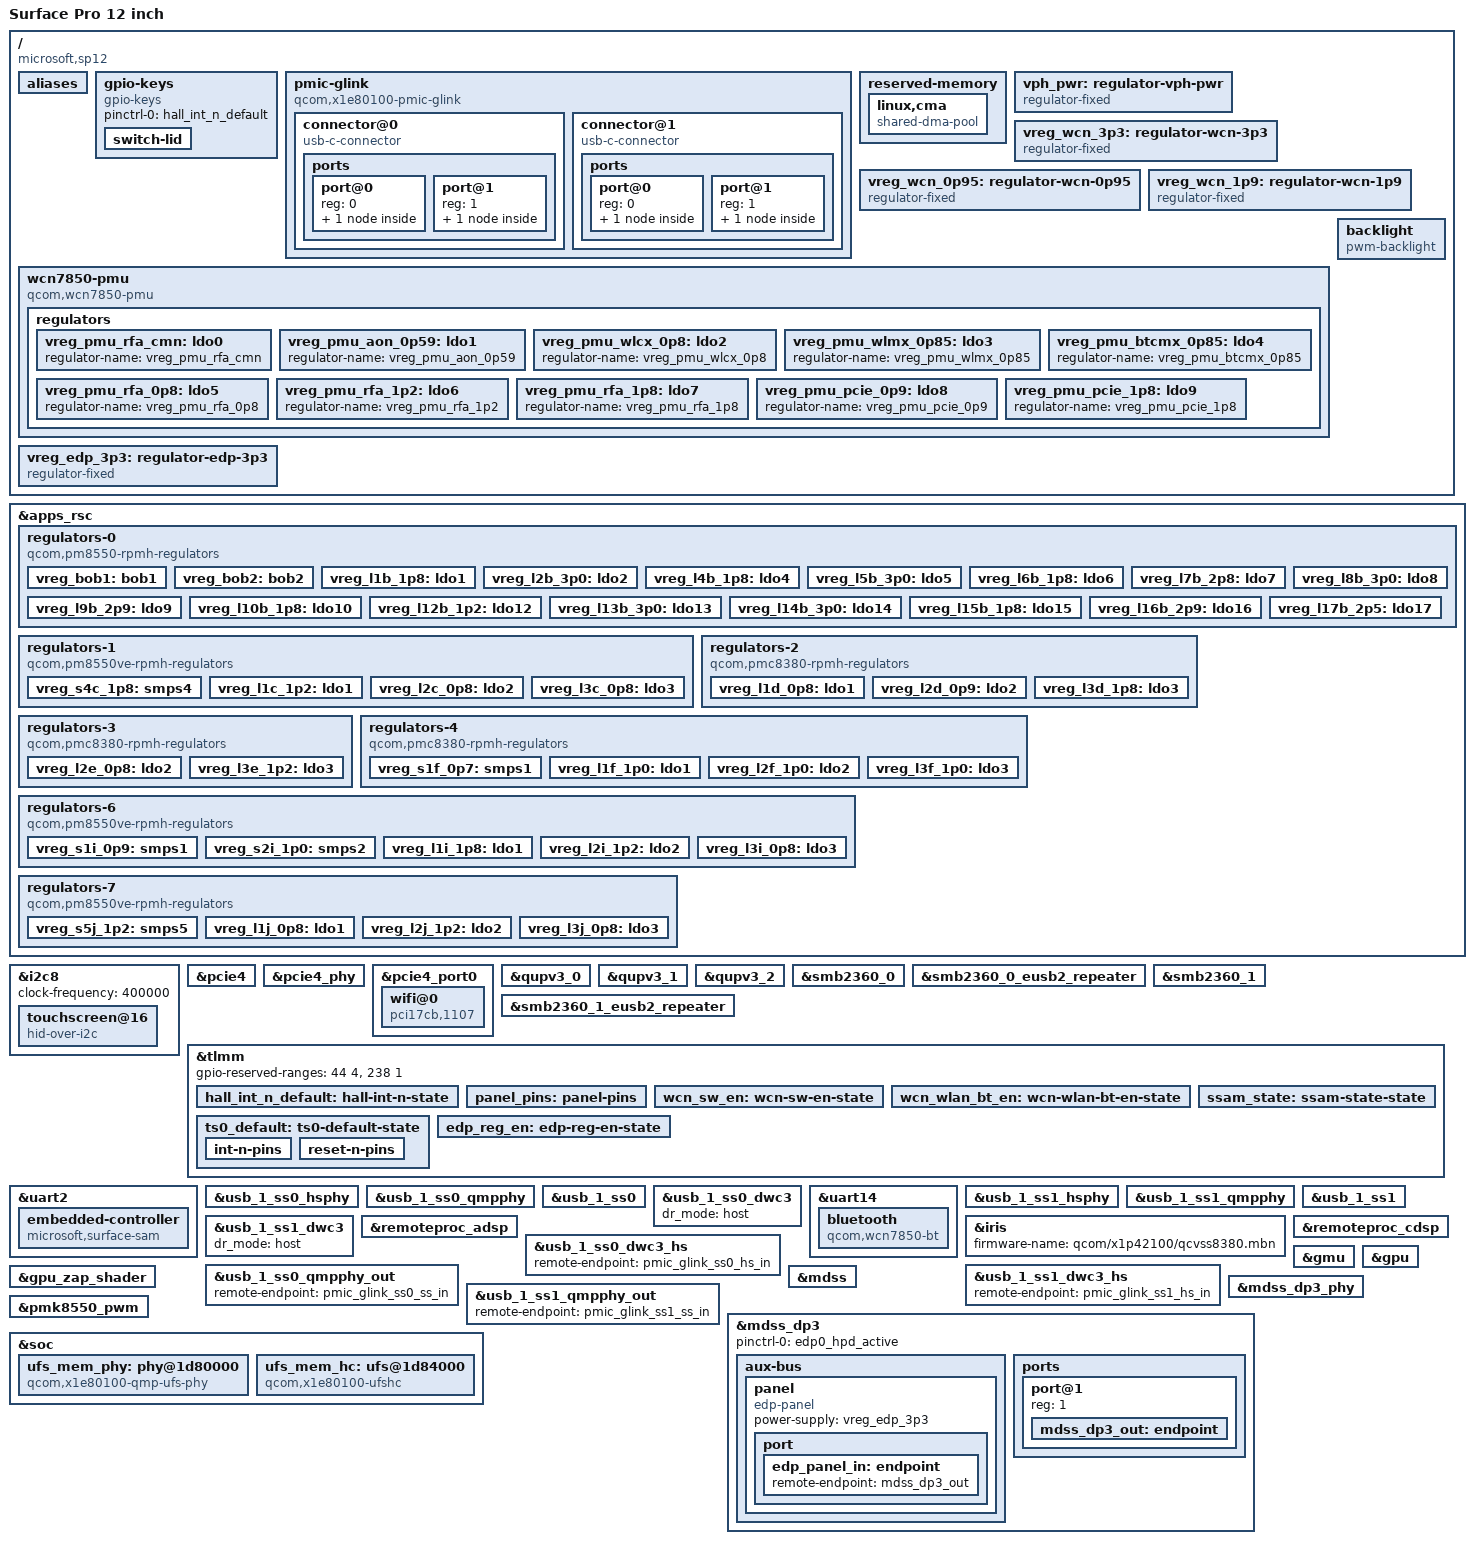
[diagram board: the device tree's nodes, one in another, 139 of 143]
// SPDX-License-Identifier: BSD-3-Clause
/*
 * Copyright (c) 2023 Qualcomm Innovation Center, Inc. All rights reserved.
 * Copyright (c) 2024, Linaro Limited
 * Copyright (c) 2025, Jens Glathe
 */

/dts-v1/;

#include <dt-bindings/gpio/gpio.h>
#include <dt-bindings/input/gpio-keys.h>
#include <dt-bindings/input/input.h>
#include <dt-bindings/pinctrl/qcom,pmic-gpio.h>
#include <dt-bindings/regulator/qcom,rpmh-regulator.h>
#include <dt-bindings/clock/qcom,x1e80100-tcsr.h>

#include "x1p42100.dtsi"
#include "x1e80100-pmics.dtsi"

/delete-node/ &pmc8380_6;
/delete-node/ &pmc8380_6_thermal;
/delete-node/ &pm8010;
/delete-node/ &pm8010_thermal;

/ {
	model = "Surface Pro 12 inch";
	compatible = "microsoft,sp12", "qcom,x1p42100";
	chassis-type = "tablet";

	aliases {
		serial0 = &uart2;
		serial1 = &uart14;
	};




	gpio-keys {
		compatible = "gpio-keys";

		pinctrl-0 = <&hall_int_n_default>;
		pinctrl-names = "default";

		switch-lid {
			gpios = <&tlmm 2 GPIO_ACTIVE_LOW>;
			linux,input-type = <EV_SW>;
			linux,code = <SW_LID>;
			wakeup-source;
			wakeup-event-action = <EV_ACT_DEASSERTED>;
		};
		
	};


	pmic-glink {
		compatible = "qcom,x1e80100-pmic-glink","qcom,sm8550-pmic-glink",
			     "qcom,pmic-glink";
		#address-cells = <1>;
		#size-cells = <0>;

		connector@0 {
			compatible = "usb-c-connector";
			reg = <0>;
			power-role = "dual";
			data-role = "host";
			
			ports {
				#address-cells = <1>;
				#size-cells = <0>;

				port@0 {
					reg = <0>;

					pmic_glink_ss0_hs_in: endpoint {
						remote-endpoint = <&usb_1_ss0_dwc3_hs>;
					};
				};

				port@1 {
					reg = <1>;

					pmic_glink_ss0_ss_in: endpoint {
						remote-endpoint = <&usb_1_ss0_qmpphy_out>;
					};
				};
			
			};
		};

		/* User-adjacent port */
		connector@1 {
			compatible = "usb-c-connector";
			reg = <1>;
			power-role = "dual";
			data-role = "host";
			
			ports {
				#address-cells = <1>;
				#size-cells = <0>;

				port@0 {
					reg = <0>;

					pmic_glink_ss1_hs_in: endpoint {
						remote-endpoint = <&usb_1_ss1_dwc3_hs>;
					};
				};

				port@1 {
					reg = <1>;

					pmic_glink_ss1_ss_in: endpoint {
						remote-endpoint = <&usb_1_ss1_qmpphy_out>;
					};
				};

			};
		};
	};

	reserved-memory {
		linux,cma {
			compatible = "shared-dma-pool";
			size = <0x0 0x8000000>;
			reusable;
			linux,cma-default;
		};
	};


	vph_pwr: regulator-vph-pwr {
		compatible = "regulator-fixed";

		regulator-name = "vph_pwr";
		regulator-min-microvolt = <3700000>;
		regulator-max-microvolt = <3700000>;

		//regulator-always-on;
		//regulator-boot-on;
	};

	vreg_wcn_3p3: regulator-wcn-3p3 {
		compatible = "regulator-fixed";

		regulator-name = "VREG_WCN_3P3";
		regulator-min-microvolt = <3300000>;
		regulator-max-microvolt = <3300000>;

		gpio = <&tlmm 214 GPIO_ACTIVE_HIGH>;
		enable-active-high;

		pinctrl-0 = <&wcn_sw_en>;
		pinctrl-names = "default";

		//regulator-boot-on;
	};

	/*
	 * TODO: These two regulators are actually part of the removable M.2
	 * card and not the CRD mainboard. Need to describe this differently.
	 * Functionally it works correctly, because all we need to do is to
	 * turn on the actual 3.3V supply above.
	 */
	vreg_wcn_0p95: regulator-wcn-0p95 {
		compatible = "regulator-fixed";

		regulator-name = "VREG_WCN_0P95";
		regulator-min-microvolt = <950000>;
		regulator-max-microvolt = <950000>;

		vin-supply = <&vreg_wcn_3p3>;
	};

	vreg_wcn_1p9: regulator-wcn-1p9 {
		compatible = "regulator-fixed";

		regulator-name = "VREG_WCN_1P9";
		regulator-min-microvolt = <1900000>;
		regulator-max-microvolt = <1900000>;

		vin-supply = <&vreg_wcn_3p3>;
	};

	wcn7850-pmu {
		compatible = "qcom,wcn7850-pmu";

		vdd-supply = <&vreg_wcn_0p95>;
		vddio-supply = <&vreg_l15b_1p8>;
		vddaon-supply = <&vreg_wcn_0p95>;
		vdddig-supply = <&vreg_wcn_0p95>;
		vddrfa1p2-supply = <&vreg_wcn_1p9>;
		vddrfa1p8-supply = <&vreg_wcn_1p9>;

		wlan-enable-gpios = <&tlmm 117 GPIO_ACTIVE_HIGH>;
		bt-enable-gpios = <&tlmm 116 GPIO_ACTIVE_HIGH>;

		pinctrl-0 = <&wcn_wlan_bt_en>;
		pinctrl-names = "default";

		regulators {
			vreg_pmu_rfa_cmn: ldo0 {
				regulator-name = "vreg_pmu_rfa_cmn";
			};

			vreg_pmu_aon_0p59: ldo1 {
				regulator-name = "vreg_pmu_aon_0p59";
			};

			vreg_pmu_wlcx_0p8: ldo2 {
				regulator-name = "vreg_pmu_wlcx_0p8";
			};

			vreg_pmu_wlmx_0p85: ldo3 {
				regulator-name = "vreg_pmu_wlmx_0p85";
			};

			vreg_pmu_btcmx_0p85: ldo4 {
				regulator-name = "vreg_pmu_btcmx_0p85";
			};

			vreg_pmu_rfa_0p8: ldo5 {
				regulator-name = "vreg_pmu_rfa_0p8";
			};

			vreg_pmu_rfa_1p2: ldo6 {
				regulator-name = "vreg_pmu_rfa_1p2";
			};

			vreg_pmu_rfa_1p8: ldo7 {
				regulator-name = "vreg_pmu_rfa_1p8";
			};

			vreg_pmu_pcie_0p9: ldo8 {
				regulator-name = "vreg_pmu_pcie_0p9";
			};

			vreg_pmu_pcie_1p8: ldo9 {
				regulator-name = "vreg_pmu_pcie_1p8";
			};
		};
	};
	

};


&apps_rsc {
	regulators-0 {
		compatible = "qcom,pm8550-rpmh-regulators";
		qcom,pmic-id = "b";

		vdd-bob1-supply = <&vph_pwr>;
		vdd-bob2-supply = <&vph_pwr>;
		vdd-l1-l4-l10-supply = <&vreg_s4c_1p8>;
		vdd-l2-l13-l14-supply = <&vreg_bob1>;
		vdd-l5-l16-supply = <&vreg_bob1>;
		vdd-l6-l7-supply = <&vreg_bob2>;
		vdd-l8-l9-supply = <&vreg_bob1>;
		vdd-l12-supply = <&vreg_s5j_1p2>;
		vdd-l15-supply = <&vreg_s4c_1p8>;
		vdd-l17-supply = <&vreg_bob2>;

		vreg_bob1: bob1 {
			regulator-name = "vreg_bob1";
			regulator-min-microvolt = <3008000>;
			regulator-max-microvolt = <3960000>;
			regulator-initial-mode = <RPMH_REGULATOR_MODE_HPM>;
		};

		vreg_bob2: bob2 {
			regulator-name = "vreg_bob2";
			regulator-min-microvolt = <2504000>;
			regulator-max-microvolt = <3008000>;
			regulator-initial-mode = <RPMH_REGULATOR_MODE_HPM>;
		};

		vreg_l1b_1p8: ldo1 {
			regulator-name = "vreg_l1b_1p8";
			regulator-min-microvolt = <1800000>;
			regulator-max-microvolt = <1800000>;
			regulator-initial-mode = <RPMH_REGULATOR_MODE_HPM>;
		};

		vreg_l2b_3p0: ldo2 {
			regulator-name = "vreg_l2b_3p0";
			regulator-min-microvolt = <3072000>;
			regulator-max-microvolt = <3100000>;
			regulator-initial-mode = <RPMH_REGULATOR_MODE_HPM>;
		};

		vreg_l4b_1p8: ldo4 {
			regulator-name = "vreg_l4b_1p8";
			regulator-min-microvolt = <1800000>;
			regulator-max-microvolt = <1800000>;
			regulator-initial-mode = <RPMH_REGULATOR_MODE_HPM>;
		};

		vreg_l5b_3p0: ldo5 {
			regulator-name = "vreg_l5b_3p0";
			regulator-min-microvolt = <3000000>;
			regulator-max-microvolt = <3000000>;
			regulator-initial-mode = <RPMH_REGULATOR_MODE_HPM>;
		};

		vreg_l6b_1p8: ldo6 {
			regulator-name = "vreg_l6b_1p8";
			regulator-min-microvolt = <1800000>;
			regulator-max-microvolt = <2960000>;
			regulator-initial-mode = <RPMH_REGULATOR_MODE_HPM>;
		};

		vreg_l7b_2p8: ldo7 {
			regulator-name = "vreg_l7b_2p8";
			regulator-min-microvolt = <2800000>;
			regulator-max-microvolt = <2800000>;
			regulator-initial-mode = <RPMH_REGULATOR_MODE_HPM>;
		};

		vreg_l8b_3p0: ldo8 {
			regulator-name = "vreg_l8b_3p0";
			regulator-min-microvolt = <3072000>;
			regulator-max-microvolt = <3072000>;
			regulator-initial-mode = <RPMH_REGULATOR_MODE_HPM>;
		};

		vreg_l9b_2p9: ldo9 {
			regulator-name = "vreg_l9b_2p9";
			regulator-min-microvolt = <2960000>;
			regulator-max-microvolt = <2960000>;
			regulator-initial-mode = <RPMH_REGULATOR_MODE_HPM>;
		};

		vreg_l10b_1p8: ldo10 {
			regulator-name = "vreg_l10b_1p8";
			regulator-min-microvolt = <1800000>;
			regulator-max-microvolt = <1800000>;
			regulator-initial-mode = <RPMH_REGULATOR_MODE_HPM>;
		};

		vreg_l12b_1p2: ldo12 {
			regulator-name = "vreg_l12b_1p2";
			regulator-min-microvolt = <1200000>;
			regulator-max-microvolt = <1200000>;
			regulator-initial-mode = <RPMH_REGULATOR_MODE_HPM>;
		};

		vreg_l13b_3p0: ldo13 {
			regulator-name = "vreg_l13b_3p0";
			regulator-min-microvolt = <3072000>;
			regulator-max-microvolt = <3100000>;
			regulator-initial-mode = <RPMH_REGULATOR_MODE_HPM>;
		};

		vreg_l14b_3p0: ldo14 {
			regulator-name = "vreg_l14b_3p0";
			regulator-min-microvolt = <3072000>;
			regulator-max-microvolt = <3072000>;
			regulator-initial-mode = <RPMH_REGULATOR_MODE_HPM>;
		};

		vreg_l15b_1p8: ldo15 {
			regulator-name = "vreg_l15b_1p8";
			regulator-min-microvolt = <1800000>;
			regulator-max-microvolt = <1800000>;
			regulator-initial-mode = <RPMH_REGULATOR_MODE_HPM>;
		};

		vreg_l16b_2p9: ldo16 {
			regulator-name = "vreg_l16b_2p9";
			regulator-min-microvolt = <2912000>;
			regulator-max-microvolt = <2912000>;
			regulator-initial-mode = <RPMH_REGULATOR_MODE_HPM>;
		};

		vreg_l17b_2p5: ldo17 {
			regulator-name = "vreg_l17b_2p5";
			regulator-min-microvolt = <2504000>;
			regulator-max-microvolt = <2504000>;
			regulator-initial-mode = <RPMH_REGULATOR_MODE_HPM>;
		};
	};

	regulators-1 {
		compatible = "qcom,pm8550ve-rpmh-regulators";
		qcom,pmic-id = "c";

		vdd-l1-supply = <&vreg_s5j_1p2>;
		vdd-l2-supply = <&vreg_s1f_0p7>;
		vdd-l3-supply = <&vreg_s1f_0p7>;
		vdd-s4-supply = <&vph_pwr>;

		vreg_s4c_1p8: smps4 {
			regulator-name = "vreg_s4c_1p8";
			regulator-min-microvolt = <1856000>;
			regulator-max-microvolt = <2000000>;
			regulator-initial-mode = <RPMH_REGULATOR_MODE_HPM>;
		};

		vreg_l1c_1p2: ldo1 {
			regulator-name = "vreg_l1c_1p2";
			regulator-min-microvolt = <1200000>;
			regulator-max-microvolt = <1200000>;
			regulator-initial-mode = <RPMH_REGULATOR_MODE_HPM>;
		};

		vreg_l2c_0p8: ldo2 {
			regulator-name = "vreg_l2c_0p8";
			regulator-min-microvolt = <880000>;
			regulator-max-microvolt = <920000>;
			regulator-initial-mode = <RPMH_REGULATOR_MODE_HPM>;
		};

		vreg_l3c_0p8: ldo3 {
			regulator-name = "vreg_l3c_0p8";
			regulator-min-microvolt = <880000>;
			regulator-max-microvolt = <920000>;
			regulator-initial-mode = <RPMH_REGULATOR_MODE_HPM>;
		};
	};

	regulators-2 {
		compatible = "qcom,pmc8380-rpmh-regulators";
		qcom,pmic-id = "d";

		vdd-l1-supply = <&vreg_s1f_0p7>;
		vdd-l2-supply = <&vreg_s1f_0p7>;
		vdd-l3-supply = <&vreg_s4c_1p8>;
		vdd-s1-supply = <&vph_pwr>;

		vreg_l1d_0p8: ldo1 {
			regulator-name = "vreg_l1d_0p8";
			regulator-min-microvolt = <880000>;
			regulator-max-microvolt = <920000>;
			regulator-initial-mode = <RPMH_REGULATOR_MODE_HPM>;
		};

		vreg_l2d_0p9: ldo2 {
			regulator-name = "vreg_l2d_0p9";
			regulator-min-microvolt = <912000>;
			regulator-max-microvolt = <920000>;
			regulator-initial-mode = <RPMH_REGULATOR_MODE_HPM>;
		};

		vreg_l3d_1p8: ldo3 {
			regulator-name = "vreg_l3d_1p8";
			regulator-min-microvolt = <1800000>;
			regulator-max-microvolt = <1800000>;
			regulator-initial-mode = <RPMH_REGULATOR_MODE_HPM>;
		};
	};

	regulators-3 {
		compatible = "qcom,pmc8380-rpmh-regulators";
		qcom,pmic-id = "e";

		vdd-l2-supply = <&vreg_s1f_0p7>;
		vdd-l3-supply = <&vreg_s5j_1p2>;

		vreg_l2e_0p8: ldo2 {
			regulator-name = "vreg_l2e_0p8";
			regulator-min-microvolt = <880000>;
			regulator-max-microvolt = <920000>;
			regulator-initial-mode = <RPMH_REGULATOR_MODE_HPM>;
		};

		vreg_l3e_1p2: ldo3 {
			regulator-name = "vreg_l3e_1p2";
			regulator-min-microvolt = <1200000>;
			regulator-max-microvolt = <1200000>;
			regulator-initial-mode = <RPMH_REGULATOR_MODE_HPM>;
		};
	};

	regulators-4 {
		compatible = "qcom,pmc8380-rpmh-regulators";
		qcom,pmic-id = "f";

		vdd-l1-supply = <&vreg_s5j_1p2>;
		vdd-l2-supply = <&vreg_s5j_1p2>;
		vdd-l3-supply = <&vreg_s5j_1p2>;
		vdd-s1-supply = <&vph_pwr>;

		vreg_s1f_0p7: smps1 {
			regulator-name = "vreg_s1f_0p7";
			regulator-min-microvolt = <700000>;
			regulator-max-microvolt = <1100000>;
			regulator-initial-mode = <RPMH_REGULATOR_MODE_HPM>;
		};

		vreg_l1f_1p0: ldo1 {
			regulator-name = "vreg_l1f_1p0";
			regulator-min-microvolt = <1024000>;
			regulator-max-microvolt = <1024000>;
			regulator-initial-mode = <RPMH_REGULATOR_MODE_HPM>;
		};

		vreg_l2f_1p0: ldo2 {
			regulator-name = "vreg_l2f_1p0";
			regulator-min-microvolt = <1024000>;
			regulator-max-microvolt = <1024000>;
			regulator-initial-mode = <RPMH_REGULATOR_MODE_HPM>;
		};

		vreg_l3f_1p0: ldo3 {
			regulator-name = "vreg_l3f_1p0";
			regulator-min-microvolt = <1024000>;
			regulator-max-microvolt = <1024000>;
			regulator-initial-mode = <RPMH_REGULATOR_MODE_HPM>;
		};
	};

	regulators-6 {
		compatible = "qcom,pm8550ve-rpmh-regulators";
		qcom,pmic-id = "i";

		vdd-l1-supply = <&vreg_s4c_1p8>;
		vdd-l2-supply = <&vreg_s5j_1p2>;
		vdd-l3-supply = <&vreg_s1f_0p7>;
		vdd-s1-supply = <&vph_pwr>;
		vdd-s2-supply = <&vph_pwr>;

		vreg_s1i_0p9: smps1 {
			regulator-name = "vreg_s1i_0p9";
			regulator-min-microvolt = <900000>;
			regulator-max-microvolt = <920000>;
			regulator-initial-mode = <RPMH_REGULATOR_MODE_HPM>;
		};

		vreg_s2i_1p0: smps2 {
			regulator-name = "vreg_s2i_1p0";
			regulator-min-microvolt = <1000000>;
			regulator-max-microvolt = <1100000>;
			regulator-initial-mode = <RPMH_REGULATOR_MODE_HPM>;
		};

		vreg_l1i_1p8: ldo1 {
			regulator-name = "vreg_l1i_1p8";
			regulator-min-microvolt = <1800000>;
			regulator-max-microvolt = <1800000>;
			regulator-initial-mode = <RPMH_REGULATOR_MODE_HPM>;
		};

		vreg_l2i_1p2: ldo2 {
			regulator-name = "vreg_l2i_1p2";
			regulator-min-microvolt = <1128000>;
			regulator-max-microvolt = <1272000>;
			regulator-initial-mode = <RPMH_REGULATOR_MODE_LPM>;
		};

		vreg_l3i_0p8: ldo3 {
			regulator-name = "vreg_l3i_0p8";
			regulator-min-microvolt = <880000>;
			regulator-max-microvolt = <920000>;
			regulator-initial-mode = <RPMH_REGULATOR_MODE_HPM>;
		};
	};

	regulators-7 {
		compatible = "qcom,pm8550ve-rpmh-regulators";
		qcom,pmic-id = "j";

		vdd-l1-supply = <&vreg_s1f_0p7>;
		vdd-l2-supply = <&vreg_s5j_1p2>;
		vdd-l3-supply = <&vreg_s1f_0p7>;
		vdd-s5-supply = <&vph_pwr>;

		vreg_s5j_1p2: smps5 {
			regulator-name = "vreg_s5j_1p2";
			regulator-min-microvolt = <1256000>;
			regulator-max-microvolt = <1304000>;
			regulator-initial-mode = <RPMH_REGULATOR_MODE_HPM>;
		};

		vreg_l1j_0p8: ldo1 {
			regulator-name = "vreg_l1j_0p8";
			regulator-min-microvolt = <880000>;
			regulator-max-microvolt = <920000>;
			regulator-initial-mode = <RPMH_REGULATOR_MODE_HPM>;
		};

		vreg_l2j_1p2: ldo2 {
			regulator-name = "vreg_l2j_1p2";
			regulator-min-microvolt = <1200000>;
			regulator-max-microvolt = <1200000>;
			regulator-initial-mode = <RPMH_REGULATOR_MODE_HPM>;
		};

		vreg_l3j_0p8: ldo3 {
			regulator-name = "vreg_l3j_0p8";
			regulator-min-microvolt = <880000>;
			regulator-max-microvolt = <920000>;
			regulator-initial-mode = <RPMH_REGULATOR_MODE_HPM>;
		};
	};
};











&i2c8 {
	clock-frequency = <400000>;

	status = "okay";

	/* ILIT2911 or GTCH1563 */
	touchscreen@16 {
		compatible = "hid-over-i2c";
		reg = <0x16>;

		hid-descr-addr = <0x1>;
		interrupts-extended = <&tlmm 51 IRQ_TYPE_LEVEL_LOW>;


		vddl-supply = <&vreg_l15b_1p8>;

		pinctrl-0 = <&ts0_default>;
		pinctrl-names = "default";
	};
};



&pcie4 {
	perst-gpios = <&tlmm 146 GPIO_ACTIVE_LOW>;
	wake-gpios = <&tlmm 148 GPIO_ACTIVE_LOW>;

	//pinctrl-0 = <&pcie4_default>;
	pinctrl-names = "default";

	status = "okay";
};

&pcie4_phy {
	vdda-phy-supply = <&vreg_l3i_0p8>;
	vdda-pll-supply = <&vreg_l3e_1p2>;

	status = "okay";
};

&pcie4_port0 {
	wifi@0 {
		compatible = "pci17cb,1107";
		reg = <0x10000 0x0 0x0 0x0 0x0>;

		vddaon-supply = <&vreg_pmu_aon_0p59>;
		vddwlcx-supply = <&vreg_pmu_wlcx_0p8>;
		vddwlmx-supply = <&vreg_pmu_wlmx_0p85>;
		vddrfacmn-supply = <&vreg_pmu_rfa_cmn>;
		vddrfa0p8-supply = <&vreg_pmu_rfa_0p8>;
		vddrfa1p2-supply = <&vreg_pmu_rfa_1p2>;
		vddrfa1p8-supply = <&vreg_pmu_rfa_1p8>;
		vddpcie0p9-supply = <&vreg_pmu_pcie_0p9>;
		vddpcie1p8-supply = <&vreg_pmu_pcie_1p8>;
	};
};




&qupv3_0 {
	status = "okay";
};

&qupv3_1 {
	status = "okay";
};

&qupv3_2 {
	status = "okay";
};

&smb2360_0 {
	status = "okay";
};

&smb2360_0_eusb2_repeater {
	vdd18-supply = <&vreg_l3d_1p8>;
	vdd3-supply = <&vreg_l2b_3p0>;
};

&smb2360_1 {
	status = "okay";
};

&smb2360_1_eusb2_repeater {
	vdd18-supply = <&vreg_l3d_1p8>;
	vdd3-supply = <&vreg_l14b_3p0>;
};




&tlmm {
	gpio-reserved-ranges = <44 4>,
		<238 1>; /* UFS Reset */



	hall_int_n_default: hall-int-n-state {
		pins = "gpio2";
		function = "gpio";
		bias-disable;
	};



	panel_pins: panel-pins {
		pins = "gpio29";
		function = "gpio";
		drive-strength = <2>;
		bias-disable;
		output-low;
	};


	wcn_sw_en: wcn-sw-en-state {
		pins = "gpio214";
		function = "gpio";
		drive-strength = <2>;
		bias-disable;
	};

	wcn_wlan_bt_en: wcn-wlan-bt-en-state {
		pins = "gpio116", "gpio117";
		function = "gpio";
		drive-strength = <2>;
		bias-disable;
	};


	ssam_state: ssam-state-state {
		pins = "gpio91";
		function = "gpio";
		bias-disable;
	};

	ts0_default: ts0-default-state {
		int-n-pins {
			pins = "gpio51";
			function = "gpio";
			bias-disable;
		};

		reset-n-pins {
			pins = "gpio52";
			function = "gpio";
			output-high;
			drive-strength = <16>;
		};
	};


};

&uart2 {
	status = "okay";

	embedded-controller {
		compatible = "microsoft,surface-sam";

		interrupts-extended = <&tlmm 91 IRQ_TYPE_EDGE_RISING>;

		current-speed = <4000000>;

		pinctrl-0 = <&ssam_state>;
		pinctrl-names = "default";
	};
};

&usb_1_ss0_hsphy {
	vdd-supply = <&vreg_l3j_0p8>;
	vdda12-supply = <&vreg_l2j_1p2>;

	phys = <&smb2360_0_eusb2_repeater>;

	status = "okay";
};

&usb_1_ss0_qmpphy {
	vdda-phy-supply = <&vreg_l3e_1p2>;
	vdda-pll-supply = <&vreg_l1j_0p8>;

	status = "okay";
};

&usb_1_ss0 {
	status = "okay";
};

&usb_1_ss0_dwc3 {
	dr_mode = "host";
};


&uart14 {
	status = "okay";

	bluetooth {
		compatible = "qcom,wcn7850-bt";
		max-speed = <3200000>;

		vddaon-supply = <&vreg_pmu_aon_0p59>;
		vddwlcx-supply = <&vreg_pmu_wlcx_0p8>;
		vddwlmx-supply = <&vreg_pmu_wlmx_0p85>;
		vddrfacmn-supply = <&vreg_pmu_rfa_cmn>;
		vddrfa0p8-supply = <&vreg_pmu_rfa_0p8>;
		vddrfa1p2-supply = <&vreg_pmu_rfa_1p2>;
		vddrfa1p8-supply = <&vreg_pmu_rfa_1p8>;
	};
};



&usb_1_ss1_hsphy {
	vdd-supply = <&vreg_l3j_0p8>;
	vdda12-supply = <&vreg_l2j_1p2>;

	phys = <&smb2360_1_eusb2_repeater>;

	status = "okay";
};

&usb_1_ss1_qmpphy {
	vdda-phy-supply = <&vreg_l2j_1p2>;
	vdda-pll-supply = <&vreg_l2d_0p9>;

	status = "okay";
};

&usb_1_ss1 {
	status = "okay";
};

&usb_1_ss1_dwc3 {
	dr_mode = "host";
};


&iris {
	firmware-name = "qcom/x1p42100/qcvss8380.mbn";
	status="okay";
};



&remoteproc_adsp {
	firmware-name = "qcom/x1p42100/qcadsp8380.mbn", "qcom/x1p42100/adsp_dtbs.elf";

	status = "okay";
};

&remoteproc_cdsp {
	firmware-name = "qcom/x1p42100/qccdsp8380.mbn", "qcom/x1p42100/cdsp_dtbs.elf";

	status = "okay";
};

&usb_1_ss0_dwc3_hs {
	remote-endpoint = <&pmic_glink_ss0_hs_in>;
};

&usb_1_ss0_qmpphy_out {
	remote-endpoint = <&pmic_glink_ss0_ss_in>;
};

&usb_1_ss1_dwc3_hs {
	remote-endpoint = <&pmic_glink_ss1_hs_in>;
};

&usb_1_ss1_qmpphy_out {
	remote-endpoint = <&pmic_glink_ss1_ss_in>;
};



/* DISPLAY */

// Gpu power management
&gmu {
	//status = "okay";
};

// Graphics Pocessing Unit
&gpu {
	status = "okay";
};

&gpu_zap_shader {
		firmware-name = "qcom/x1p42100/qcdxkmsucpurwa.mbn";
};

// Display system
&mdss {
	status = "okay";
};

// Internal Display Port
&mdss_dp3_phy {
	vdda-phy-supply = <&vreg_l3j_0p8>;
	vdda-pll-supply = <&vreg_l2j_1p2>;

	status = "okay";
};

&mdss_dp3 {
	/delete-property/ #sound-dai-cells;

	pinctrl-names = "default";
	pinctrl-0 = <&edp0_hpd_active>;

	status = "okay";

	aux-bus {
		panel {
			compatible = "edp-panel";

			power-supply = <&vreg_edp_3p3>;

			port {
				edp_panel_in: endpoint {
					remote-endpoint = <&mdss_dp3_out>;
				};
			};
		};
	};

	ports {
		port@1 {
			reg = <1>;

			mdss_dp3_out: endpoint {
				data-lanes = <0 1 2 3>;
				link-frequencies = /bits/ 64 <1620000000 2700000000 5400000000 8100000000>;

				remote-endpoint = <&edp_panel_in>;
			};
		};
	};
};

// Backlight
/ {
	backlight: backlight {
		compatible = "pwm-backlight";
		pwms = <&pmk8550_pwm 0 5000000>;		

		power-supply = <&vreg_edp_3p3>;

	};


	// Backlight power regulator
	vreg_edp_3p3: regulator-edp-3p3 {
		compatible = "regulator-fixed";

		regulator-name = "VREG_EDP_3P3";
		regulator-min-microvolt = <3300000>;
		regulator-max-microvolt = <3300000>;

		gpio = <&tlmm 70 GPIO_ACTIVE_HIGH>;
		enable-active-high;

		pinctrl-0 = <&edp_reg_en>;
		pinctrl-names = "default";

		//regulator-boot-on;
		
	};	

};

// Backlight PWM Controller
&pmk8550_pwm {
	status = "okay";
};

// backlight power control pins
&tlmm {
		edp_reg_en: edp-reg-en-state {
		pins = "gpio70";
		function = "gpio";
		drive-strength = <2>;
		bias-disable;
		output-high;
	};
};


&soc {
		ufs_mem_phy: phy@1d80000 {
			compatible = "qcom,x1e80100-qmp-ufs-phy";
			reg = <0 0x01d80000 0 0x2000>;
			clocks = <&rpmhcc RPMH_CXO_CLK>,
				 <&gcc GCC_UFS_PHY_PHY_AUX_CLK>,
				 <&tcsr TCSR_UFS_PHY_CLKREF_EN>;
			clock-names = "ref",
				      "ref_aux",
				      "qref";

			dma-coherent;
			power-domains = <&gcc GCC_UFS_PHY_GDSC>;
			resets = <&ufs_mem_hc 0>;
			reset-names = "ufsphy";
			#phy-cells = <0>;
			status = "disabled";

		};

		ufs_mem_hc: ufs@1d84000 {
			compatible = "qcom,x1e80100-ufshc", "qcom,ufshc",
				     "jedec,ufs-2.0";
			reg = <0 0x01d84000 0 0x3000>;
			interrupts = <GIC_SPI 265 IRQ_TYPE_LEVEL_HIGH>;
			phys = <&ufs_mem_phy>;
			phy-names = "ufsphy";
			lanes-per-direction = <2>;
			#reset-cells = <1>;
			resets = <&gcc GCC_UFS_PHY_BCR>;
			reset-names = "rst";
			dma-coherent;

			power-domains = <&gcc GCC_UFS_PHY_GDSC>;

			iommus = <&apps_smmu 0x1a0 0x0>;

			clock-names = "core_clk",
				      "bus_aggr_clk",
				      "iface_clk",
				      "core_clk_unipro",
				      "ref_clk",
				      "tx_lane0_sync_clk",
				      "rx_lane0_sync_clk",
				      "rx_lane1_sync_clk";
			clocks = <&gcc GCC_UFS_PHY_AXI_CLK>,
				 <&gcc GCC_AGGRE_UFS_PHY_AXI_CLK>,
				 <&gcc GCC_UFS_PHY_AHB_CLK>,
				 <&gcc GCC_UFS_PHY_UNIPRO_CORE_CLK>,
				 <&rpmhcc RPMH_CXO_CLK>,
				 <&gcc GCC_UFS_PHY_TX_SYMBOL_0_CLK>,
				 <&gcc GCC_UFS_PHY_RX_SYMBOL_0_CLK>,
				 <&gcc GCC_UFS_PHY_RX_SYMBOL_1_CLK>;
			freq-table-hz = <300000000 300000000>,
					<0 0>,
					<0 0>,
					<300000000 300000000>,
					<0 0>,
					<0 0>,
					<0 0>,
					<0 0>;

			interconnects = <&aggre1_noc MASTER_UFS_MEM QCOM_ICC_TAG_ALWAYS
					 &mc_virt SLAVE_EBI1 QCOM_ICC_TAG_ALWAYS>,
					<&gem_noc MASTER_APPSS_PROC QCOM_ICC_TAG_ALWAYS
					 &config_noc SLAVE_UFS_MEM_CFG QCOM_ICC_TAG_ALWAYS>;
			interconnect-names = "ufs-ddr", "cpu-ufs";

			qcom,ice-supported;

			status = "disabled";
		};

		

};

&ufs_mem_hc {
	status = "okay";

	reset-gpios = <&tlmm 210 GPIO_ACTIVE_LOW>;
	vcc-supply = <&vreg_l17b_2p5>;
	vcc-max-microamp = <1300000>;
	vccq-supply = <&vreg_l2i_1p2>;
	vccq-max-microamp = <1200000>;
	vdd-hba-supply = <&vreg_l3j_0p8>;

};

&ufs_mem_phy {
	status = "okay";

	vdda-phy-supply = <&vreg_l3e_1p2>;
	vdda-pll-supply = <&vreg_l3i_0p8>;
};
// sgb4 3j,17b,2i,3e,3i, 9b,6b,12b,9b,6b,12b,6b,
/*
&gcc {
			#clock-cells = <1>;
	clocks = <&bi_tcxo_div2>,
				 <&sleep_clk>,
				 <&pcie3_phy>,
				 <&pcie4_phy>,
				 <&pcie5_phy>,
				 <&pcie6a_phy>,
				 <&ufs_mem_phy>,
				 <&ufs_mem_hc>,
				 <&usb_1_ss0_qmpphy QMP_USB43DP_USB3_PIPE_CLK>,
				 <&usb_1_ss1_qmpphy QMP_USB43DP_USB3_PIPE_CLK>,
				 <&usb_1_ss2_qmpphy QMP_USB43DP_USB3_PIPE_CLK>;
};*/
/*
&aggre1_noc {

			clocks = <&gcc GCC_AGGRE_UFS_PHY_AXI_CLK>;
};*/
